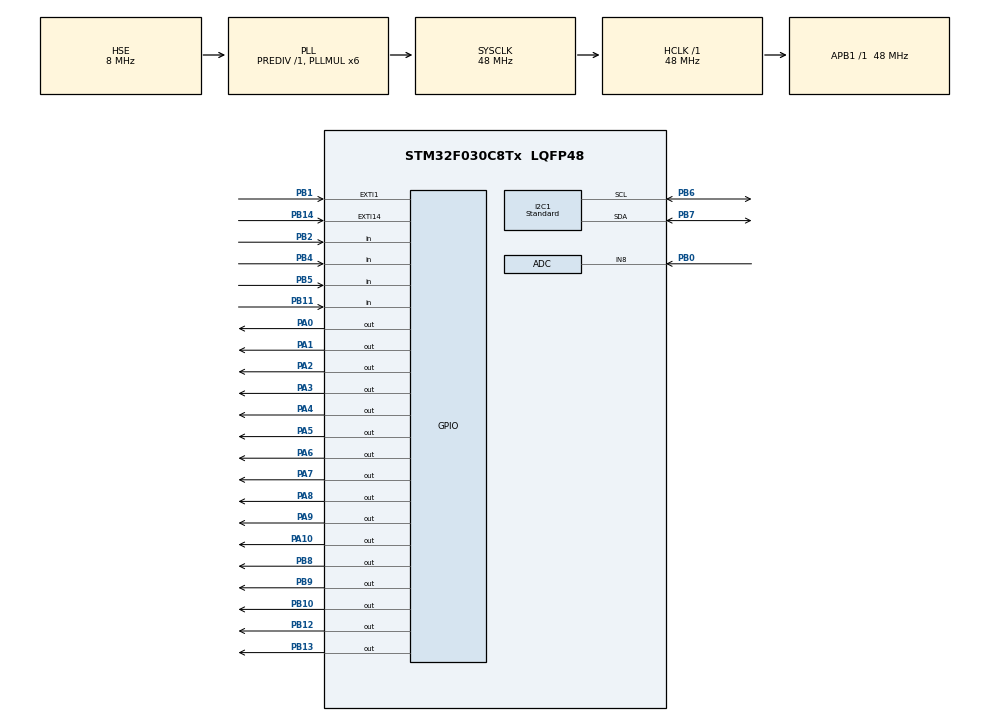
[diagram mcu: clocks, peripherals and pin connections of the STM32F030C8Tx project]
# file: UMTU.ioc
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ADC.Resolution=ADC_RESOLUTION_12B
I2C1.I2C_Speed_Mode=I2C_Standard
Mcu.Family=STM32F0
Mcu.Name=STM32F030C8Tx
Mcu.Package=LQFP48
NVIC.EXTI0_1_IRQn=true\:1\:0\:true\:false\:true\:true\:true
NVIC.EXTI4_15_IRQn=true\:0\:0\:true\:false\:true\:true\:true
NVIC.TIM14_IRQn=true\:0\:0\:true\:false\:true\:true\:true
PA0.GPIO_Speed=GPIO_SPEED_FREQ_LOW
PA0.Signal=GPIO_Output
PA1.GPIO_Speed=GPIO_SPEED_FREQ_LOW
PA1.Signal=GPIO_Output
PA10.PinState=GPIO_PIN_SET
PA10.Signal=GPIO_Output
PA13.Mode=Serial_Wire
PA13.Signal=SYS_SWDIO
PA14.Mode=Serial_Wire
PA14.Signal=SYS_SWCLK
PA2.GPIO_Speed=GPIO_SPEED_FREQ_LOW
PA2.Signal=GPIO_Output
PA3.GPIO_Speed=GPIO_SPEED_FREQ_LOW
PA3.Signal=GPIO_Output
PA4.GPIO_Speed=GPIO_SPEED_FREQ_LOW
PA4.Signal=GPIO_Output
PA5.GPIO_Speed=GPIO_SPEED_FREQ_LOW
PA5.Signal=GPIO_Output
PA6.GPIO_Speed=GPIO_SPEED_FREQ_LOW
PA6.Signal=GPIO_Output
PA7.GPIO_Speed=GPIO_SPEED_FREQ_LOW
PA7.Signal=GPIO_Output
PA8.PinState=GPIO_PIN_SET
PA8.Signal=GPIO_Output
PA9.PinState=GPIO_PIN_SET
PA9.Signal=GPIO_Output
PB0.Mode=IN8
PB0.Signal=ADC_IN8
PB1.GPIO_ModeDefaultEXTI=GPIO_MODE_IT_FALLING
PB1.Signal=GPXTI1
PB10.GPIO_Speed=GPIO_SPEED_FREQ_HIGH
PB10.Signal=GPIO_Output
PB11.GPIO_PuPd=GPIO_PULLUP
PB11.Signal=GPIO_Input
PB12.GPIO_PuPd=GPIO_PULLDOWN
PB12.Signal=GPIO_Output
PB13.GPIO_PuPd=GPIO_PULLDOWN
PB13.Signal=GPIO_Output
PB14.GPIO_ModeDefaultEXTI=GPIO_MODE_IT_RISING
PB14.Signal=GPXTI14
PB2.GPIO_PuPd=GPIO_PULLDOWN
PB2.Signal=GPIO_Input
PB4.GPIO_PuPd=GPIO_PULLDOWN
PB4.Signal=GPIO_Input
PB5.GPIO_PuPd=GPIO_PULLDOWN
PB5.Signal=GPIO_Input
PB6.Mode=I2C
PB6.Signal=I2C1_SCL
PB7.Mode=I2C
PB7.Signal=I2C1_SDA
PB8.GPIO_Speed=GPIO_SPEED_FREQ_HIGH
PB8.Signal=GPIO_Output
PB9.GPIO_Speed=GPIO_SPEED_FREQ_HIGH
PB9.Signal=GPIO_Output
PF0-OSC_IN.Mode=HSE-External-Oscillator
PF0-OSC_IN.Signal=RCC_OSC_IN
PF1-OSC_OUT.Mode=HSE-External-Oscillator
PF1-OSC_OUT.Signal=RCC_OSC_OUT
ProjectManager.HeapSize=0x200
ProjectManager.StackSize=0x400
ProjectManager.TargetToolchain=STM32CubeIDE
RCC.AHBFreq_Value=48000000
RCC.APB1Freq_Value=48000000
RCC.APB1TimFreq_Value=48000000
RCC.HCLKFreq_Value=48000000
RCC.PLLMUL=RCC_PLL_MUL6
RCC.PLLSourceVirtual=RCC_PLLSOURCE_HSE
RCC.SYSCLKFreq_VALUE=48000000
RCC.SYSCLKSource=RCC_SYSCLKSOURCE_PLLCLK
TIM14.Prescaler=4800-1
VP_TIM14_VS_ClockSourceINT.Mode=Enable_Timer
board=custom

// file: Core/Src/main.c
/* USER CODE BEGIN Header */
/**
  ******************************************************************************
  * @file           : main.c
  * @brief          : Main program body
  ******************************************************************************
  * @attention
  *
  * <h2><center>&copy; Copyright (c) 2020 STMicroelectronics.
  * All rights reserved.</center></h2>
  *
  * This software component is licensed by ST under BSD 3-Clause license,
  * the "License"; You may not use this file except in compliance with the
  * License. You may obtain a copy of the License at:
  *                        opensource.org/licenses/BSD-3-Clause
  *
  ******************************************************************************
  */
/* USER CODE END Header */
#include "main.h"

/* USER CODE BEGIN Includes */
#include "lcd.h"
#include "gui.h"
#include "stdlib.h"
/* USER CODE END Includes */

ADC_HandleTypeDef hadc;

I2C_HandleTypeDef hi2c1;

TIM_HandleTypeDef htim14;

void SystemClock_Config(void);
static void MX_GPIO_Init(void);
static void MX_I2C1_Init(void);
static void MX_ADC_Init(void);
static void MX_TIM14_Init(void);

int main(void)
{

  /* MCU Configuration--------------------------------------------------------*/

  /* Reset of all peripherals, Initializes the Flash interface and the Systick. */
  HAL_Init();

  /* Configure the system clock */
  SystemClock_Config();

  /* Initialize all configured peripherals */
  MX_GPIO_Init();
  MX_I2C1_Init();
  MX_ADC_Init();
  MX_TIM14_Init();
  /* USER CODE BEGIN 2 */

HAL_GPIO_WritePin(GPIOA, GPIO_PIN_8, GPIO_PIN_SET);
HAL_GPIO_WritePin(GPIOA, GPIO_PIN_9, GPIO_PIN_SET);
HAL_GPIO_WritePin(GPIOA, GPIO_PIN_10, GPIO_PIN_SET);
gui();
  /* USER CODE END 2 */

  /* Infinite loop */
  while (1)
  {

  }
}

void SystemClock_Config(void)
{
  RCC_OscInitTypeDef RCC_OscInitStruct = {0};
  RCC_ClkInitTypeDef RCC_ClkInitStruct = {0};
  RCC_PeriphCLKInitTypeDef PeriphClkInit = {0};

  /** Initializes the RCC Oscillators according to the specified parameters
  * in the RCC_OscInitTypeDef structure.
  */
  RCC_OscInitStruct.OscillatorType = RCC_OSCILLATORTYPE_HSI|RCC_OSCILLATORTYPE_HSI14
                              |RCC_OSCILLATORTYPE_HSE;
  RCC_OscInitStruct.HSEState = RCC_HSE_ON;
  RCC_OscInitStruct.HSIState = RCC_HSI_ON;
  RCC_OscInitStruct.HSI14State = RCC_HSI14_ON;
  RCC_OscInitStruct.HSICalibrationValue = RCC_HSICALIBRATION_DEFAULT;
  RCC_OscInitStruct.HSI14CalibrationValue = 16;
  RCC_OscInitStruct.PLL.PLLState = RCC_PLL_ON;
  RCC_OscInitStruct.PLL.PLLSource = RCC_PLLSOURCE_HSE;
  RCC_OscInitStruct.PLL.PLLMUL = RCC_PLL_MUL6;
  RCC_OscInitStruct.PLL.PREDIV = RCC_PREDIV_DIV1;
  if (HAL_RCC_OscConfig(&RCC_OscInitStruct) != HAL_OK)
  {
    Error_Handler();
  }
  /** Initializes the CPU, AHB and APB buses clocks
  */
  RCC_ClkInitStruct.ClockType = RCC_CLOCKTYPE_HCLK|RCC_CLOCKTYPE_SYSCLK
                              |RCC_CLOCKTYPE_PCLK1;
  RCC_ClkInitStruct.SYSCLKSource = RCC_SYSCLKSOURCE_PLLCLK;
  RCC_ClkInitStruct.AHBCLKDivider = RCC_SYSCLK_DIV1;
  RCC_ClkInitStruct.APB1CLKDivider = RCC_HCLK_DIV1;

  if (HAL_RCC_ClockConfig(&RCC_ClkInitStruct, FLASH_LATENCY_1) != HAL_OK)
  {
    Error_Handler();
  }
  PeriphClkInit.PeriphClockSelection = RCC_PERIPHCLK_I2C1;
  PeriphClkInit.I2c1ClockSelection = RCC_I2C1CLKSOURCE_HSI;
  if (HAL_RCCEx_PeriphCLKConfig(&PeriphClkInit) != HAL_OK)
  {
    Error_Handler();
  }
}

static void MX_ADC_Init(void)
{

  ADC_ChannelConfTypeDef sConfig = {0};

  /** Configure the global features of the ADC (Clock, Resolution, Data Alignment and number of conversion)
  */
  hadc.Instance = ADC1;
  hadc.Init.ClockPrescaler = ADC_CLOCK_ASYNC_DIV1;
  hadc.Init.Resolution = ADC_RESOLUTION_12B;
  hadc.Init.DataAlign = ADC_DATAALIGN_RIGHT;
  hadc.Init.ScanConvMode = ADC_SCAN_DIRECTION_FORWARD;
  hadc.Init.EOCSelection = ADC_EOC_SINGLE_CONV;
  hadc.Init.LowPowerAutoWait = DISABLE;
  hadc.Init.LowPowerAutoPowerOff = DISABLE;
  hadc.Init.ContinuousConvMode = DISABLE;
  hadc.Init.DiscontinuousConvMode = DISABLE;
  hadc.Init.ExternalTrigConv = ADC_SOFTWARE_START;
  hadc.Init.ExternalTrigConvEdge = ADC_EXTERNALTRIGCONVEDGE_NONE;
  hadc.Init.DMAContinuousRequests = DISABLE;
  hadc.Init.Overrun = ADC_OVR_DATA_PRESERVED;
  if (HAL_ADC_Init(&hadc) != HAL_OK)
  {
    Error_Handler();
  }
  /** Configure for the selected ADC regular channel to be converted.
  */
  sConfig.Channel = ADC_CHANNEL_8;
  sConfig.Rank = ADC_RANK_CHANNEL_NUMBER;
  sConfig.SamplingTime = ADC_SAMPLETIME_1CYCLE_5;
  if (HAL_ADC_ConfigChannel(&hadc, &sConfig) != HAL_OK)
  {
    Error_Handler();
  }

}

static void MX_I2C1_Init(void)
{

  hi2c1.Instance = I2C1;
  hi2c1.Init.Timing = 0x2000090E;
  hi2c1.Init.OwnAddress1 = 0;
  hi2c1.Init.AddressingMode = I2C_ADDRESSINGMODE_7BIT;
  hi2c1.Init.DualAddressMode = I2C_DUALADDRESS_DISABLE;
  hi2c1.Init.OwnAddress2 = 0;
  hi2c1.Init.OwnAddress2Masks = I2C_OA2_NOMASK;
  hi2c1.Init.GeneralCallMode = I2C_GENERALCALL_DISABLE;
  hi2c1.Init.NoStretchMode = I2C_NOSTRETCH_DISABLE;
  if (HAL_I2C_Init(&hi2c1) != HAL_OK)
  {
    Error_Handler();
  }
  /** Configure Analogue filter
  */
  if (HAL_I2CEx_ConfigAnalogFilter(&hi2c1, I2C_ANALOGFILTER_ENABLE) != HAL_OK)
  {
    Error_Handler();
  }
  /** Configure Digital filter
  */
  if (HAL_I2CEx_ConfigDigitalFilter(&hi2c1, 0) != HAL_OK)
  {
    Error_Handler();
  }

}

static void MX_TIM14_Init(void)
{

  htim14.Instance = TIM14;
  htim14.Init.Prescaler = 4800-1;
  htim14.Init.CounterMode = TIM_COUNTERMODE_UP;
  htim14.Init.Period = 65535;
  htim14.Init.ClockDivision = TIM_CLOCKDIVISION_DIV1;
  htim14.Init.AutoReloadPreload = TIM_AUTORELOAD_PRELOAD_DISABLE;
  if (HAL_TIM_Base_Init(&htim14) != HAL_OK)
  {
    Error_Handler();
  }

}

static void MX_GPIO_Init(void)
{
  GPIO_InitTypeDef GPIO_InitStruct = {0};

  /* GPIO Ports Clock Enable */
  __HAL_RCC_GPIOF_CLK_ENABLE();
  __HAL_RCC_GPIOA_CLK_ENABLE();
  __HAL_RCC_GPIOB_CLK_ENABLE();

  /*Configure GPIO pin Output Level */
  HAL_GPIO_WritePin(GPIOA, GPIO_PIN_0|GPIO_PIN_1|GPIO_PIN_2|GPIO_PIN_3
                          |GPIO_PIN_4|GPIO_PIN_5|GPIO_PIN_6|GPIO_PIN_7, GPIO_PIN_RESET);

  /*Configure GPIO pin Output Level */
  HAL_GPIO_WritePin(GPIOB, GPIO_PIN_10|GPIO_PIN_12|GPIO_PIN_13|GPIO_PIN_8
                          |GPIO_PIN_9, GPIO_PIN_RESET);

  /*Configure GPIO pin Output Level */
  HAL_GPIO_WritePin(GPIOA, GPIO_PIN_8|GPIO_PIN_9|GPIO_PIN_10, GPIO_PIN_SET);

  /*Configure GPIO pins : PA0 PA1 PA2 PA3
                           PA4 PA5 PA6 PA7
                           PA8 PA9 PA10 */
  GPIO_InitStruct.Pin = GPIO_PIN_0|GPIO_PIN_1|GPIO_PIN_2|GPIO_PIN_3
                          |GPIO_PIN_4|GPIO_PIN_5|GPIO_PIN_6|GPIO_PIN_7
                          |GPIO_PIN_8|GPIO_PIN_9|GPIO_PIN_10;
  GPIO_InitStruct.Mode = GPIO_MODE_OUTPUT_PP;
  GPIO_InitStruct.Pull = GPIO_NOPULL;
  GPIO_InitStruct.Speed = GPIO_SPEED_FREQ_LOW;
  HAL_GPIO_Init(GPIOA, &GPIO_InitStruct);

  /*Configure GPIO pin : PB1 */
  GPIO_InitStruct.Pin = GPIO_PIN_1;
  GPIO_InitStruct.Mode = GPIO_MODE_IT_FALLING;
  GPIO_InitStruct.Pull = GPIO_NOPULL;
  HAL_GPIO_Init(GPIOB, &GPIO_InitStruct);

  /*Configure GPIO pins : PB2 PB4 PB5 */
  GPIO_InitStruct.Pin = GPIO_PIN_2|GPIO_PIN_4|GPIO_PIN_5;
  GPIO_InitStruct.Mode = GPIO_MODE_INPUT;
  GPIO_InitStruct.Pull = GPIO_PULLDOWN;
  HAL_GPIO_Init(GPIOB, &GPIO_InitStruct);

  /*Configure GPIO pins : PB10 PB8 PB9 */
  GPIO_InitStruct.Pin = GPIO_PIN_10|GPIO_PIN_8|GPIO_PIN_9;
  GPIO_InitStruct.Mode = GPIO_MODE_OUTPUT_PP;
  GPIO_InitStruct.Pull = GPIO_NOPULL;
  GPIO_InitStruct.Speed = GPIO_SPEED_FREQ_HIGH;
  HAL_GPIO_Init(GPIOB, &GPIO_InitStruct);

  /*Configure GPIO pin : PB11 */
  GPIO_InitStruct.Pin = GPIO_PIN_11;
  GPIO_InitStruct.Mode = GPIO_MODE_INPUT;
  GPIO_InitStruct.Pull = GPIO_PULLUP;
  HAL_GPIO_Init(GPIOB, &GPIO_InitStruct);

  /*Configure GPIO pins : PB12 PB13 */
  GPIO_InitStruct.Pin = GPIO_PIN_12|GPIO_PIN_13;
  GPIO_InitStruct.Mode = GPIO_MODE_OUTPUT_PP;
  GPIO_InitStruct.Pull = GPIO_PULLDOWN;
  GPIO_InitStruct.Speed = GPIO_SPEED_FREQ_LOW;
  HAL_GPIO_Init(GPIOB, &GPIO_InitStruct);

  /*Configure GPIO pin : PB14 */
  GPIO_InitStruct.Pin = GPIO_PIN_14;
  GPIO_InitStruct.Mode = GPIO_MODE_IT_RISING;
  GPIO_InitStruct.Pull = GPIO_NOPULL;
  HAL_GPIO_Init(GPIOB, &GPIO_InitStruct);

  /* EXTI interrupt init*/
  HAL_NVIC_SetPriority(EXTI0_1_IRQn, 1, 0);
  HAL_NVIC_EnableIRQ(EXTI0_1_IRQn);

  HAL_NVIC_SetPriority(EXTI4_15_IRQn, 0, 0);
  HAL_NVIC_EnableIRQ(EXTI4_15_IRQn);

}

void Error_Handler(void)
{
}

/************************ (C) COPYRIGHT STMicroelectronics *****END OF FILE****/
